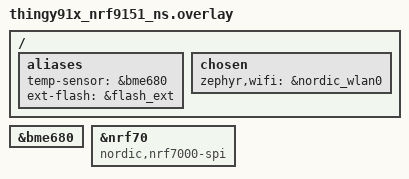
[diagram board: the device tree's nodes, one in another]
/*
 * Copyright (c) 2024 Nordic Semiconductor ASA
 *
 * SPDX-License-Identifier: LicenseRef-Nordic-5-Clause
 */

#include <thingy91x_wifi.dtsi>

/ {
	aliases {
		temp-sensor = &bme680;
		ext-flash = &flash_ext;
	};

	chosen {
		zephyr,wifi = &nordic_wlan0;
	};
};

&bme680 {
	status = "okay";
};

/* Switch to nrf7000 emulation so that scan-only mode is used. */
&nrf70 {
	compatible = "nordic,nrf7000-spi";
};
